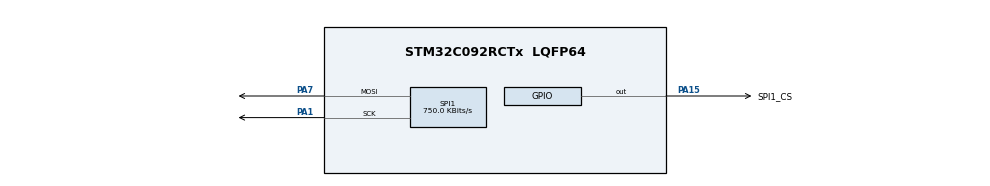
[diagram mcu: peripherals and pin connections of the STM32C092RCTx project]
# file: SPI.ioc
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Mcu.Family=STM32C0
Mcu.Name=STM32C092RCTx
Mcu.Package=LQFP64
NUCLEO-C092RC.BUTTON=1
NUCLEO-C092RC.LD1=true
NUCLEO-C092RC.LD2=true
NUCLEO-C092RC.VCP=true
NVIC.EXTI4_15_IRQn=true\:0\:0\:false\:false\:true\:false\:true\:true
PA1.Mode=TX_Only_Simplex_Unidirect_Master
PA1.Signal=SPI1_SCK
PA13.GPIO_Label=SWDIO
PA13.Signal=DEBUG_SWDIO
PA14-BOOT0.GPIO_Label=SWCLK
PA14-BOOT0.Signal=DEBUG_SWCLK
PA15.GPIO_Label=SPI1_CS
PA15.PinState=GPIO_PIN_SET
PA15.Signal=GPIO_Output
PA2.Signal=USART2_TX
PA3.Signal=USART2_RX
PA7.Mode=TX_Only_Simplex_Unidirect_Master
PA7.Signal=SPI1_MOSI
PC14-OSCX_IN(PC14).GPIO_Label=OSCX_IN
PC14-OSCX_IN(PC14).Signal=RCC_OSCX_IN
PC15-OSCX_OUT(PC15).GPIO_Label=OSCX_OUT
PC15-OSCX_OUT(PC15).Signal=RCC_OSCX_OUT
PF0-OSC_IN(PF0).GPIO_Label=OSC_IN
PF0-OSC_IN(PF0).Signal=RCC_OSC_IN
PF1-OSC_OUT(PF1).GPIO_Label=OSC_OUT
PF1-OSC_OUT(PF1).Signal=RCC_OSC_OUT
ProjectManager.HeapSize=0x200
ProjectManager.StackSize=0x400
ProjectManager.TargetToolchain=STM32CubeIDE
RCC.ADCFreq_Value=12000000
RCC.AHBFreq_Value=12000000
RCC.CortexFreq_Value=12000000
RCC.EXTERNAL_CLOCK_VALUE=12288000
RCC.HCLKFreq_Value=12000000
RCC.HSE_VALUE=8000000
RCC.HSI_VALUE=48000000
RCC.LSE_VALUE=32768
RCC.SYSCLKFreq_VALUE=12000000
SPI1.BaudRatePrescaler=SPI_BAUDRATEPRESCALER_16
SPI1.CalculateBaudRate=750.0 KBits/s
SPI1.DataSize=SPI_DATASIZE_8BIT
SPI1.Direction=SPI_DIRECTION_2LINES
SPI1.Mode=SPI_MODE_MASTER
SPI1.VirtualType=VM_MASTER
VP_NUCLEO-C092RC_VS_BSP_COMMON.Mode=COMMON
board=NUCLEO-C092RC

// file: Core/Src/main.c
/* USER CODE BEGIN Header */
/**
  ******************************************************************************
  * @file           : main.c
  * @brief          : Main program body
  ******************************************************************************
  * @attention
  *
  * Copyright (c) 2026 STMicroelectronics.
  * All rights reserved.
  *
  * This software is licensed under terms that can be found in the LICENSE file
  * in the root directory of this software component.
  * If no LICENSE file comes with this software, it is provided AS-IS.
  *
  ******************************************************************************
  */
/* USER CODE END Header */
#include "main.h"

COM_InitTypeDef BspCOMInit;

SPI_HandleTypeDef hspi1;

/* USER CODE BEGIN PV */
uint8_t dataToSend = 'A';
/* USER CODE END PV */

void SystemClock_Config(void);
static void MX_GPIO_Init(void);
static void MX_SPI1_Init(void);

int main(void)
{

  /* MCU Configuration--------------------------------------------------------*/

  /* Reset of all peripherals, Initializes the Flash interface and the Systick. */
  HAL_Init();

  /* Configure the system clock */
  SystemClock_Config();

  /* Initialize all configured peripherals */
  MX_GPIO_Init();
  MX_SPI1_Init();

  /* Initialize leds */
  BSP_LED_Init(LED_GREEN);
  BSP_LED_Init(LED_BLUE);

  /* Initialize USER push-button, will be used to trigger an interrupt each time it's pressed.*/
  BSP_PB_Init(BUTTON_USER, BUTTON_MODE_EXTI);

  /* Initialize COM1 port (115200, 8 bits (7-bit data + 1 stop bit), no parity */
  BspCOMInit.BaudRate   = 115200;
  BspCOMInit.WordLength = COM_WORDLENGTH_8B;
  BspCOMInit.StopBits   = COM_STOPBITS_1;
  BspCOMInit.Parity     = COM_PARITY_NONE;
  BspCOMInit.HwFlowCtl  = COM_HWCONTROL_NONE;
  if (BSP_COM_Init(COM1, &BspCOMInit) != BSP_ERROR_NONE)
  {
    Error_Handler();
  }

  /* Infinite loop */
  /* USER CODE BEGIN WHILE */
  while (1)
  {
	      HAL_GPIO_WritePin(GPIOA, GPIO_PIN_15, GPIO_PIN_RESET);
	      HAL_SPI_Transmit(&hspi1, &dataToSend, 1, 10);
	      HAL_GPIO_WritePin(GPIOA, GPIO_PIN_15, GPIO_PIN_SET);
	      dataToSend++;
	      if (dataToSend > 'Z') {
	        dataToSend = 'A';
	      }
	      HAL_Delay(1000);
    /* USER CODE END WHILE */

  }
}

void SystemClock_Config(void)
{
  RCC_OscInitTypeDef RCC_OscInitStruct = {0};
  RCC_ClkInitTypeDef RCC_ClkInitStruct = {0};

  __HAL_FLASH_SET_LATENCY(FLASH_LATENCY_0);

  /** Initializes the RCC Oscillators according to the specified parameters
  * in the RCC_OscInitTypeDef structure.
  */
  RCC_OscInitStruct.OscillatorType = RCC_OSCILLATORTYPE_HSI;
  RCC_OscInitStruct.HSIState = RCC_HSI_ON;
  RCC_OscInitStruct.HSIDiv = RCC_HSI_DIV4;
  RCC_OscInitStruct.HSICalibrationValue = RCC_HSICALIBRATION_DEFAULT;
  if (HAL_RCC_OscConfig(&RCC_OscInitStruct) != HAL_OK)
  {
    Error_Handler();
  }

  /** Initializes the CPU, AHB and APB buses clocks
  */
  RCC_ClkInitStruct.ClockType = RCC_CLOCKTYPE_HCLK|RCC_CLOCKTYPE_SYSCLK
                              |RCC_CLOCKTYPE_PCLK1;
  RCC_ClkInitStruct.SYSCLKSource = RCC_SYSCLKSOURCE_HSI;
  RCC_ClkInitStruct.SYSCLKDivider = RCC_SYSCLK_DIV1;
  RCC_ClkInitStruct.AHBCLKDivider = RCC_HCLK_DIV1;
  RCC_ClkInitStruct.APB1CLKDivider = RCC_APB1_DIV1;

  if (HAL_RCC_ClockConfig(&RCC_ClkInitStruct, FLASH_LATENCY_0) != HAL_OK)
  {
    Error_Handler();
  }
}

static void MX_SPI1_Init(void)
{

  /* SPI1 parameter configuration*/
  hspi1.Instance = SPI1;
  hspi1.Init.Mode = SPI_MODE_MASTER;
  hspi1.Init.Direction = SPI_DIRECTION_2LINES;
  hspi1.Init.DataSize = SPI_DATASIZE_8BIT;
  hspi1.Init.CLKPolarity = SPI_POLARITY_LOW;
  hspi1.Init.CLKPhase = SPI_PHASE_1EDGE;
  hspi1.Init.NSS = SPI_NSS_SOFT;
  hspi1.Init.BaudRatePrescaler = SPI_BAUDRATEPRESCALER_16;
  hspi1.Init.FirstBit = SPI_FIRSTBIT_MSB;
  hspi1.Init.TIMode = SPI_TIMODE_DISABLE;
  hspi1.Init.CRCCalculation = SPI_CRCCALCULATION_DISABLE;
  hspi1.Init.CRCPolynomial = 7;
  hspi1.Init.CRCLength = SPI_CRC_LENGTH_DATASIZE;
  hspi1.Init.NSSPMode = SPI_NSS_PULSE_ENABLE;
  if (HAL_SPI_Init(&hspi1) != HAL_OK)
  {
    Error_Handler();
  }

}

static void MX_GPIO_Init(void)
{
  GPIO_InitTypeDef GPIO_InitStruct = {0};

  /* GPIO Ports Clock Enable */
  __HAL_RCC_GPIOC_CLK_ENABLE();
  __HAL_RCC_GPIOF_CLK_ENABLE();
  __HAL_RCC_GPIOA_CLK_ENABLE();

  /*Configure GPIO pin Output Level */
  HAL_GPIO_WritePin(SPI1_CS_GPIO_Port, SPI1_CS_Pin, GPIO_PIN_SET);

  /*Configure GPIO pin : SPI1_CS_Pin */
  GPIO_InitStruct.Pin = SPI1_CS_Pin;
  GPIO_InitStruct.Mode = GPIO_MODE_OUTPUT_PP;
  GPIO_InitStruct.Pull = GPIO_NOPULL;
  GPIO_InitStruct.Speed = GPIO_SPEED_FREQ_LOW;
  HAL_GPIO_Init(SPI1_CS_GPIO_Port, &GPIO_InitStruct);

}

void Error_Handler(void)
{
  __disable_irq();
  while (1)
  {
  }
}
